# RN821X_RN721X_SOC_B register map
File version: v1.0.6
Renergy Metering RN821X RN721X SOC
CPU: CM0 r0p0, little endian, no MPU, no FPU, 3 interrupt priority bits
Registers are 32-bit, read-write, reset 0x0 unless marked. A register's access mark holds for its fields unless they carry their own. Offsets are from the block's base; lines under a group give offsets from that group; [hi:lo] are bit positions; {n}, {i} and the like mark numbered series; 'fields as' and 'values as' point back to an identical list; <NAME> marks a mode.

## Memory map
0x40000000 UART0 size 0x18 — UART tranceiver
0x40004000 UART1 size 0x18
0x40008000 UART2 size 0x18
0x4000C000 UART3 size 0x18
0x40010000 TC0 size 0x34 — A 32-bit timer
0x40014000 TC1 size 0x34
0x40018000 UART4 size 0x18
0x4001C000 UART5 size 0x18
0x40020000 SPI0 size 0x38 — synchronous peripheral interface
0x40024000 I2C size 0x14 — I2C controller
0x40028000 KBI size 0x10 — key detection
0x4002C000 MADC size 0x44 — analog peripherals
0x40030000 WDT size 0x20 — watchdog timer
0x40034000 SYSCTL size 0x11C — system control
0x40038000 ISO7816 size 0x24 — ISO7816 interface
0x4003C000 RTC size 0x18C — real time clock
0x40040000 NVM size 0x58 — no voltage module
0x40044000 INTC size 0x10 — interrupt controller for off-chip interrupt requests
0x40048000 LCD size 0x46 — liquid crystal display
0x50000000 GPIO size 0x110
0x50004000 EMU size 0x4D0 — energy metering unit

## Interrupts
0 SYSCLKCAL (SYSCTL) — 16 SYSCLK CALC or EMU_RCD(v2/v3) Interrupt
3 RTC — 19 RTC Interrupt
4 EMU — 20 EMU or D2F(v2) Interrupt
5 MADC — 21 MADC or FLK(v2) Interrupt
6 UART0 — 22 UART0 Interrupt
7 UART1 — 23 UART1 Interrupt
8 UART2 — 24 UART2 Interrupt
9 UART3 — 25 UART3 Interrupt
10 SPI0 — 26 SPI0(except v3) Interrupt
11 I2C — 27 IIC Interrupt
12 ISO78160 (ISO7816) — 28 ISO7816 0(except v3) and SPI3(v2/v3) Interrupt
13 ISO78161 (ISO7816) — 29 ISO7816 1(except v3) and SPI2(v2) Interrupt
14 TC0 — 30 Timer/Counter 0(except v3) Interrupt
15 TC1 — 31 Timer/Counter 1 Interrupt
16 UART4 — 32 UART4 Interrupt
17 UART5 — 33 UART5 Interrupt
18 WDT — 34 Watch Dog Interrupt
19 KBI — 35 Key Interrupt
20 LCD — 36 LCD and DSP(v2) Interrupt
23 NVM — 39 NVM or SPI1 Interrupt
24 EXT0 (INTC) — 40 Extern0 Interrupt (or all extern irq)

## MADC — analog peripherals
Base 0x4002C000
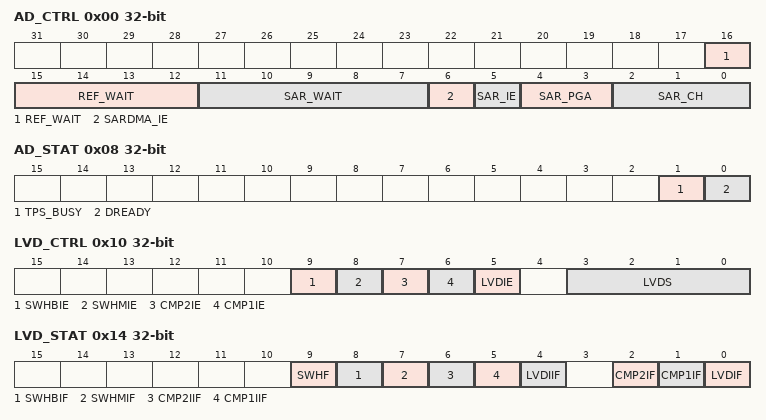
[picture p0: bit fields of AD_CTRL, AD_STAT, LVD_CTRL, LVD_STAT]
0x00 AD_CTRL — SAR ADC control register
  [16:12] REF_WAIT — set voltage reference duration config bits((REF_WAIT+1)*30.5us) between REF enable and ADC enable
  [11:7] SAR_WAIT — set SAR ADC duration config bits((SAR_WAIT+1)*30.5us) between enable and sample
  [6] SARDMA_IE — SAR DMA enable/disable bit
    0=DIS (do not generate interrupt request on SAR event); 1=EN (generate interrupt request on SAR event)
  [5] SAR_IE — SAR ADC interrupt enable bit
    values as SARDMA_IE
  [4:3] SAR_PGA — SAR ADC PGA selection bits
    0=0P5 (select SAR ADC PGA as 0.5); 1=select SAR ADC PGA as 1; 2=1P5 (select SAR ADC PGA as 1.5); 3=select SAR ADC PGA as 2
  [2:0] SAR_CH — SAR ADC channel selection bits(part1)
0x04 AD_START — SAR ADC start register
  [0] AD_START — SAR ADC start control bit, =1 start sar-measure once
0x08 AD_STAT — SAR ADC status register
  [1] TPS_BUSY ro — automatic temperature measurement busy flag
    0=IDLE (no outstanding automatic temperature measurement); 1=BUSY (pending automatic temperature measurement)
  [0] DREADY write-1-clears — SAR ADC data ready/pending flag
    0=PEND (SAR ADC data pending flag); 1=READY (SAR ADC data ready flag)
0x0C AD_DATA ro — SAR ADC data register
  [9:0] AD_DATA — SAR ADC result data bits
0x10 LVD_CTRL — LVD control register
  [9] SWHBIE — change to battery interrupt enable bit
    0=DIS (disable interrupt); 1=EN (enable interrupt)
  [8] SWHMIE — change to main power interrupt enable bit
    0=DIS (disable interrupt); 1=EN (enable interrupt)
  [7] CMP2IE — comparator No.2 interrupt enable bit
    0=DIS (disable interrupt); 1=EN (enable interrupt)
  [6] CMP1IE — comparator No.1 interrupt enable bit
    0=DIS (disable interrupt); 1=EN (enable interrupt)
  [5] LVDIE — LVD interrupt enable bit
    0=DIS (disable interrupt); 1=EN (enable interrupt)
  [3:0] LVDS — LVD threshold voltage set bits
    0=2P3 (select 2.3 as LVD Vil, 2.4 as LVD Vih); 1=2P5 (select 2.5 as LVD Vil, 2.6 as LVD Vih); 2=2P7 (select 2.7 as LVD Vil, 2.8 as LVD Vih); 3=2P9 (select 2.9 as LVD Vil, 3.0 as LVD Vih); 4=3P1 (select 3.1 as LVD Vil, 3.2 as LVD Vih); 5=3P3 (select 3.3 as LVD Vil, 3.4 as LVD Vih); 6=3P5 (select 3.5 as LVD Vil, 3.6 as LVD Vih); 7=3P7 (select 3.7 as LVD Vil, 3.8 as LVD Vih); 8=3P9 (select 3.9 as LVD Vil, 4.0 as LVD Vih); 9=4P0 (select 4.0 as LVD Vil, 4.1 as LVD Vih); 10=4P2 (select 4.2 as LVD Vil, 4.3 as LVD Vih); 11=4P4 (select 4.4 as LVD Vil, 4.5 as LVD Vih); 12=4P6 (select 4.6 as LVD Vil, 4.7 as LVD Vih); 13=4P7 (select 4.7 as LVD Vil, 4.8 as LVD Vih); 14=LVDIN (select 1.25 as LVD Vil, 1.45 as LVD Vih ,and compare with voltage found on LVDIN pin)
0x14 LVD_STAT — LVD status register
  [9] SWHF ro — power change status bit
    0=M (power selected as main power mode); 1=B (power selected as battery mode)
  [8] SWHBIF write-1-clears — change to battery interrupt flag
    0=NUL (event not generated); 1=OCC (interrupt event generated)
  [7] SWHMIF write-1-clears — change to main power interrupt flag
    values as SWHBIF
  [6] CMP2IIF write-1-clears — comparator No.2 interrupt flag
    values as SWHBIF
  [5] CMP1IIF write-1-clears — comparator NO.1 interrupt flag
    values as SWHBIF
  [4] LVDIIF write-1-clears — LVD interrupt flag
    values as SWHBIF
  [2] CMP2IF ro — comparator No.2 status flag
    0=L (status flag, lower than threshold); 1=H (status flag, higher than threshold)
  [1] CMP1IF ro — comparator NO.1 status flag
    values as CMP2IF
  [0] LVDIF ro — LVD status flag
    values as CMP2IF
